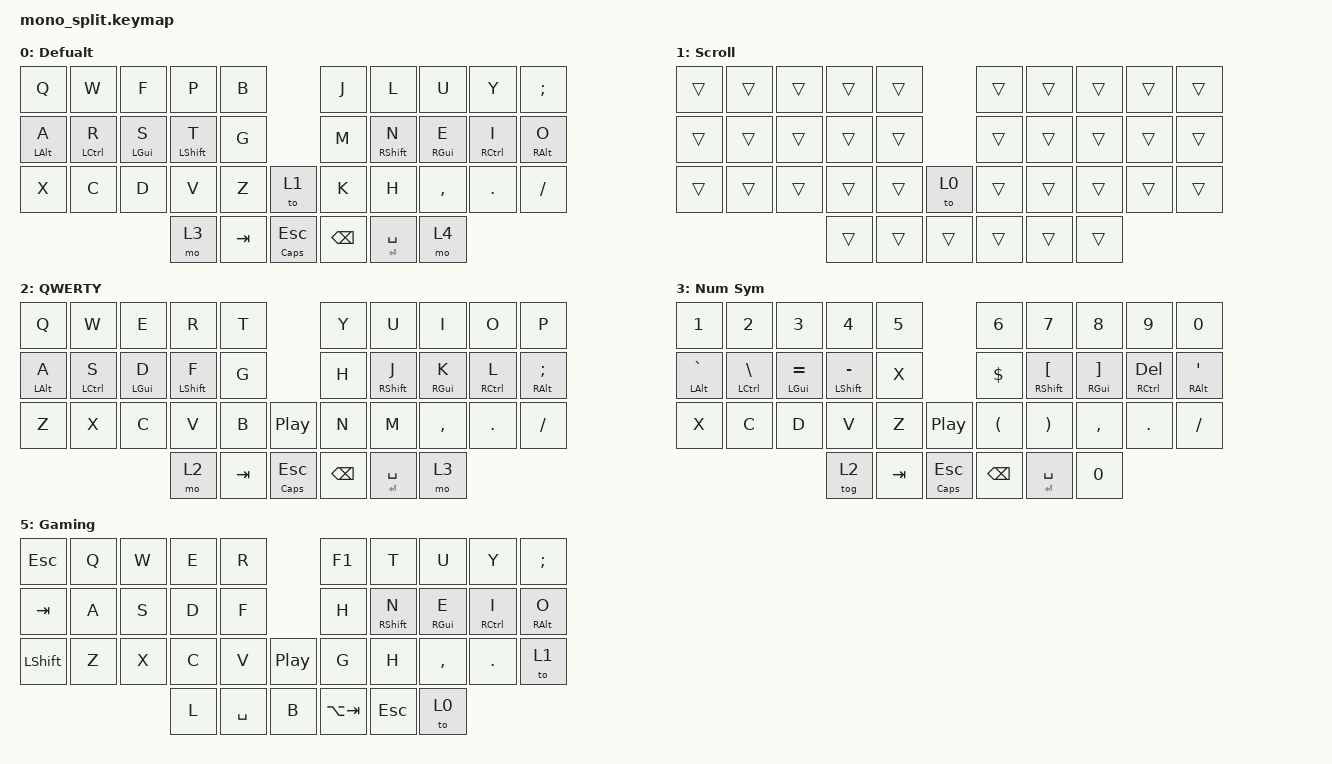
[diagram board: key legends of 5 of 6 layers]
#include <behaviors.dtsi>
#include <dt-bindings/zmk/keys.h>
#include <dt-bindings/zmk/bt.h>
#include <dt-bindings/zmk/outputs.h>
#define ZMK_MOUSE_SCRL_VAL 60
#include <dt-bindings/zmk/pointing.h>

/ {
    behaviors {
        hm: homerow_mods {
            compatible = "zmk,behavior-hold-tap";
            #binding-cells = <2>;
            tapping-term-ms = <200>;
            flavor = "tap-preferred";
            bindings = <&kp>, <&kp>;
        };
    };

    scroll_wheel: scroll_wheel {
        compatible = "zmk,behavior-sensor-rotate";
        #sensor-binding-cells = <0>;
        bindings = <&msc SCRL_DOWN>, <&msc SCRL_UP>;
        tap-ms = <120>; // Forces the OS to catch the ultra-fast scroll tick
    };

    keymap {
        compatible = "zmk,keymap";

        colemak_dh {
            display-name = "Defualt";
            // -----------------------------------------------------------------------------------------------
            // |   Q   |   W   |   F   |   P   |   B   |             |   J   |   L   |   U   |   Y   |   ;   |
            // | A/ALT | R/CTRL| S/CMD |T/SHIFT|   G   |             |   M   |   N   |   E   |   I   |   O   |
            // |   X   |   C   |   D   |   V   |   Z   |             |   K   |   H   |   ,   |   .   |   /   |
            //                         |   F   |  TAB  |  ESC | BSPC | SPACE |   F   |
            bindings = <
                &kp Q       &kp W       &kp F       &kp P        &kp B                           &kp J      &kp L       &kp U       &kp Y       &kp SEMICOLON   
                &hm LALT A  &hm LCTRL R &hm LGUI S  &hm LSHIFT T &kp G                           &kp M      &hm RSHIFT N  &hm RGUI E &hm RCTRL I  &hm RALT O
                &kp X       &kp C       &kp D       &kp V        &kp Z            &to 1          &kp K      &kp H       &kp COMMA   &kp DOT     &kp SLASH
                                                    &mo 3        &kp TAB  &hm CAPS ESC &kp BSPC  &hm ENTER SPACE &mo 4
            >;

            sensor-bindings = <&inc_dec_kp C_VOL_DN C_VOL_UP>;
        };

        scroll {
            display-name = "Scroll";
            // -----------------------------------------------------------------------------------------------
            // |   Q   |   W   |   F   |   P   |   B   |             |   J   |   L   |   U   |   Y   |   ;   |
            // | A/ALT | R/CTRL| S/CMD |T/SHIFT|   G   |             |   M   |   N   |   E   |   I   |   O   |
            // |   X   |   C   |   D   |   V   |   Z   |             |   K   |   H   |   ,   |   .   |   /   |
            //                         |   F   |  TAB  |  ESC | BSPC | SPACE |   F   |
            bindings = <
                &trans   &trans   &trans   &trans   &trans                     &trans   &trans   &trans   &trans   &trans   
                &trans   &trans   &trans   &trans   &trans                     &trans   &trans   &trans   &trans   &trans   
                &trans   &trans   &trans   &trans   &trans          &to 0      &trans   &trans   &trans   &trans   &trans   
                                           &trans   &trans   &trans &trans     &trans   &trans   
            >;

            sensor-bindings = <&scroll_wheel>;
        };

        qwerty {
            display-name = "QWERTY";
            // -----------------------------------------------------------------------------------------------
            // |   Q   |   W   |   F   |   P   |   B   |             |   J   |   L   |   U   |   Y   |   ;   |
            // | A/ALT | R/CTRL| S/CMD |T/SHIFT|   G   |             |   M   |   N   |   E   |   I   |   O   |
            // |   X   |   C   |   D   |   V   |   Z   |             |   K   |   H   |   ,   |   .   |   /   |
            //                         |   F   |  TAB  |  ESC | BSPC | SPACE |   F   |
            bindings = <
                &kp Q       &kp W       &kp E       &kp R        &kp T                           &kp Y      &kp U       &kp I       &kp O       &kp P   
                &hm LALT A  &hm LCTRL S &hm LGUI D  &hm LSHIFT F &kp G                           &kp H      &hm RSHIFT J  &hm RGUI K &hm RCTRL L  &hm RALT SEMICOLON
                &kp Z       &kp X       &kp C       &kp V        &kp B      &kp C_PLAY_PAUSE     &kp N      &kp M       &kp COMMA   &kp DOT     &kp SLASH
                                                    &mo 2        &kp TAB  &hm CAPS ESC &kp BSPC  &hm ENTER SPACE &mo 3
            >;

            sensor-bindings = <&inc_dec_kp C_VOL_DN C_VOL_UP>;
        };

        num_sym {
            display-name = "Num Sym";
            // -----------------------------------------------------------------------------------------------
            // |   Q   |   W   |   F   |   P   |   B   |             |   J   |   L   |   U   |   Y   |   ;   |
            // | ~/ALT | R/CTRL| S/CMD |T/SHIFT|   G   |             |   M   |   N   |   E   |   I   |   O   |
            // |   X   |   C   |   D   |   V   |   Z   |             |   K   |   H   |   ,   |   .   |   /   |
            //                         |   L1  |  TAB  |  ESC | BSPC | SPACE |   L2  |
            bindings = <
                &kp N1       &kp N2       &kp N3       &kp N4        &kp N5                 &kp N6       &kp N7       &kp N8       &kp N9   &kp N0  
                &hm LALT GRAVE  &hm LCTRL BSLH &hm LGUI EQUAL  &hm LSHIFT MINUS &kp X           &kp DOLLAR   &hm RSHIFT LBKT  &hm RGUI RBKT &hm RCTRL DEL  &hm RALT SQT
                &kp X       &kp C       &kp D       &kp V        &kp Z      &kp C_PLAY_PAUSE    &kp LPAR     &kp RPAR         &kp COMMA   &kp DOT     &kp SLASH
                                                    &tog 2        &kp TAB  &hm CAPS ESC &kp BSPC  &hm ENTER SPACE &kp N0
            >;

            sensor-bindings = <&inc_dec_kp C_VOL_DN C_VOL_UP>;
        };

        function {
            display-name = "Func";
            // -----------------------------------------------------------------------------------------------
            // |   Q   |   W   |   F   |   P   |   B   |             |   J   |   L   |   U   |   Y   |   ;   |
            // | A/ALT | R/CTRL| S/CMD |T/SHIFT|   G   |             |   M   |   N   |   E   |   I   |   O   |
            // |   X   |   C   |   D   |   V   |   Z   |             |   K   |   H   |   ,   |   .   |   /   |
            //                         |   F   |  TAB  |  ESC | BSPC | SPACE |   F   |
            bindings = <
                &out OUT_USB  &out OUT_BLE  &bt BT_SEL 2 &bt BT_SEL 1 &bt BT_SEL 0                    &kp F1     &kp F2    &kp F3 &kp F5     &kp F12       
                &bt BT_CLR  &none &bt BT_DISC 2 &bt BT_DISC 1 &bt BT_DISC 0                           &kp LEFT   &kp DOWN  &kp UP &kp RIGHT  &none
                &kp X       &kp C       &kp D       &kp V        &kp Z      &kp C_PLAY_PAUSE          &kp C_PREV &kp C_PLAY_PAUSE &kp C_NEXT &kp C_VOL_DN &kp C_VOL_UP
                                                    &to 4        &kp TAB  &hm CAPS ESC &kp BSPC  &hm ENTER SPACE
            >;

            sensor-bindings = <&inc_dec_kp LEFT RIGHT>;
        };

        gaming {
            display-name = "Gaming";
            // -----------------------------------------------------------------------------------------------
            // |   Q   |   W   |   F   |   P   |   B   |             |   J   |   L   |   U   |   Y   |   ;   |
            // | A/ALT | R/CTRL| S/CMD |T/SHIFT|   G   |             |   M   |   N   |   E   |   I   |   O   |
            // |   X   |   C   |   D   |   V   |   Z   |             |   K   |   H   |   ,   |   .   |   /   |
            //                         |   F   |  TAB  |  ESC | BSPC | SPACE |   F   |
            bindings = <
                &kp ESC     &kp Q  &kp W  &kp E &kp R                         &kp F1  &kp T  &kp U  &kp Y       &kp SEMICOLON   
                &kp TAB     &kp A  &kp S  &kp D &kp F                         &kp H   &hm RSHIFT N  &hm RGUI E &hm RCTRL I  &hm RALT O
                &kp LSHIFT  &kp Z  &kp X  &kp C &kp V     &kp C_PLAY_PAUSE    &kp G   &kp H       &kp COMMA   &kp DOT     &to 1
                                          &kp L &kp SPACE &kp B &kp LA(TAB) &kp ESC &to 0
            >;

            sensor-bindings = <&inc_dec_kp C_VOL_DN C_VOL_UP>;
        };
    };
 };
